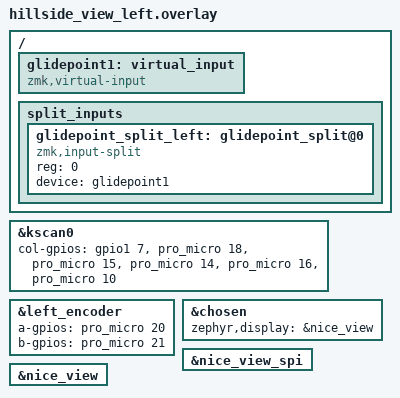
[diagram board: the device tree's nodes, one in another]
/*
 * Copyright (c) 2022 The ZMK Contributors
 *
 * SPDX-License-Identifier: MIT
 */

#include "hillside_view.dtsi"

&kscan0  {
    col-gpios
        = <&gpio1 7 GPIO_ACTIVE_HIGH>
        , <&pro_micro 18 GPIO_ACTIVE_HIGH>
        , <&pro_micro 15 GPIO_ACTIVE_HIGH>
        , <&pro_micro 14 GPIO_ACTIVE_HIGH>
        , <&pro_micro 16 GPIO_ACTIVE_HIGH>
        , <&pro_micro 10 GPIO_ACTIVE_HIGH>
        ;
};

&left_encoder {
    status = "okay";
  a-gpios = <&pro_micro 20 (GPIO_ACTIVE_HIGH | GPIO_PULL_UP)>;
  b-gpios = <&pro_micro 21 (GPIO_ACTIVE_HIGH | GPIO_PULL_UP)>;
};

&chosen {
  zephyr,display = &nice_view;
};

// nice view bus
&nice_view_spi {
  status = "okay";
};

&nice_view {
  status = "okay";
};

/* Left half now pure peripheral when using external dongle */
/* Native ZMK split input support - peripheral sends virtual input to central */

/ {
  /* Virtual input device for the left side (sent to dongle via split input) */
  glidepoint1: virtual_input {
    compatible = "zmk,virtual-input";
  };

  /* Split input configuration - connects virtual device to split transport */
  split_inputs {
    #address-cells = <1>;
    #size-cells = <0>;

    glidepoint_split_left: glidepoint_split@0 {
      compatible = "zmk,input-split";
      reg = <0>; /* Must match central's glidepoint_left reg value */
      device = <&glidepoint1>;
    };
  };
};

